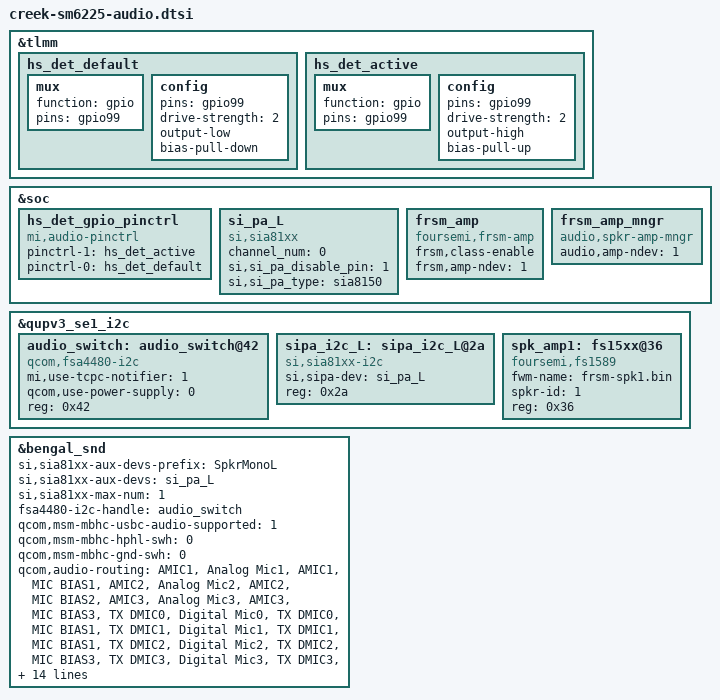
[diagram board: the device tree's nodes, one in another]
#include "xiaomi-sm6225-common.dtsi"

&tlmm {
	hs_det_default: hs_det_default {
		mux {
			function = "gpio";
			pins = "gpio99";
		};

		config {
			pins = "gpio99";
			drive-strength = <2>;
			output-low;
			bias-pull-down;
		};
	};

	hs_det_active: hs_det_active {
		mux {
			function = "gpio";
			pins = "gpio99";
		};

		config {
			pins = "gpio99";
			drive-strength = <2>;
			output-high;
			bias-pull-up;
		};
	};
};

&soc {
    hs_det_gpio_pinctrl {
		status = "okay";
		compatible = "mi,audio-pinctrl";
		pinctrl-1 = <&hs_det_active>;
		pinctrl-0 = <&hs_det_default>;
		pinctrl-names = "aud_default", "aud_active";
	};

	si_pa_L: si_pa_L {
		compatible = "si,sia81xx";
		channel_num = <0>;
		si,si_pa_disable_pin = <1>;
		si,si_pa_type = "sia8150";
	};

	frsm_amp: frsm_amp {
		status = "ok";
		frsm,class-enable;
		frsm,amp-ndev = <1>;
		compatible = "foursemi,frsm-amp";
	};

	frsm_amp_mngr: frsm_amp_mngr {
		status = "ok";
		audio,amp-ndev = <1>;
		compatible = "audio,spkr-amp-mngr";
	};
};

&qupv3_se1_i2c {
	audio_switch: audio_switch@42 {
		compatible = "qcom,fsa4480-i2c";
		mi,use-tcpc-notifier = <1>;
		qcom,use-power-supply = <0>;
		reg = <0x42>;
	};

	sipa_i2c_L: sipa_i2c_L@2a {
		si,sipa-dev = <&si_pa_L>;
		reg = <0x2a>;
		compatible = "si,sia81xx-i2c";
	};

	spk_amp1: fs15xx@36 {
		status = "ok";
		fwm-name = "frsm-spk1.bin";
		spkr-id = <1>;
		reg = <0x36>;
		compatible = "foursemi,fs1589";
	};
};

&bengal_snd {
    si,sia81xx-aux-devs-prefix = "SpkrMonoL";
    si,sia81xx-aux-devs = <&si_pa_L>;
    si,sia81xx-max-num = <1>;

    fsa4480-i2c-handle = <&audio_switch>;
    qcom,msm-mbhc-usbc-audio-supported = <1>;

    qcom,msm-mbhc-hphl-swh = <0>;
	qcom,msm-mbhc-gnd-swh = <0>;

    qcom,audio-routing =
    	"AMIC1", "Analog Mic1",
    	"AMIC1", "MIC BIAS1",
    	"AMIC2", "Analog Mic2",
    	"AMIC2", "MIC BIAS2",
    	"AMIC3", "Analog Mic3",
    	"AMIC3", "MIC BIAS3",
    	"TX DMIC0", "Digital Mic0",
    	"TX DMIC0", "MIC BIAS1",
    	"TX DMIC1", "Digital Mic1",
    	"TX DMIC1", "MIC BIAS1",
    	"TX DMIC2", "Digital Mic2",
    	"TX DMIC2", "MIC BIAS3",
    	"TX DMIC3", "Digital Mic3",
    	"TX DMIC3", "MIC BIAS3",
    	"IN1_HPHL", "HPHL_OUT",
    	"IN2_HPHR", "HPHR_OUT",
    	"IN3_AUX", "AUX_OUT",
    	"RX_TX DEC0_INP", "TX DEC0 MUX",
    	"RX_TX DEC1_INP", "TX DEC1 MUX",
    	"RX_TX DEC2_INP", "TX DEC2 MUX",
    	"RX_TX DEC3_INP", "TX DEC3 MUX",
    	"TX SWR_INPUT", "WCD_TX_OUTPUT",
    	"VA SWR_INPUT", "VA_SWR_CLK",
    	"VA SWR_INPUT", "WCD_TX_OUTPUT",
    	"TX_AIF1 CAP", "VA_SWR_CLK",
    	"TX_AIF2 CAP", "VA_SWR_CLK",
    	"TX_AIF3 CAP", "VA_SWR_CLK",
    	"VA DMIC0", "Digital Mic0",
    	"VA DMIC1", "Digital Mic1",
    	"VA DMIC2", "Digital Mic2",
    	"VA DMIC3", "Digital Mic3",
    	"VA DMIC0", "VA MIC BIAS1",
    	"VA DMIC1", "VA MIC BIAS1",
    	"VA DMIC2", "VA MIC BIAS3",
    	"VA DMIC3", "VA MIC BIAS3";
};
